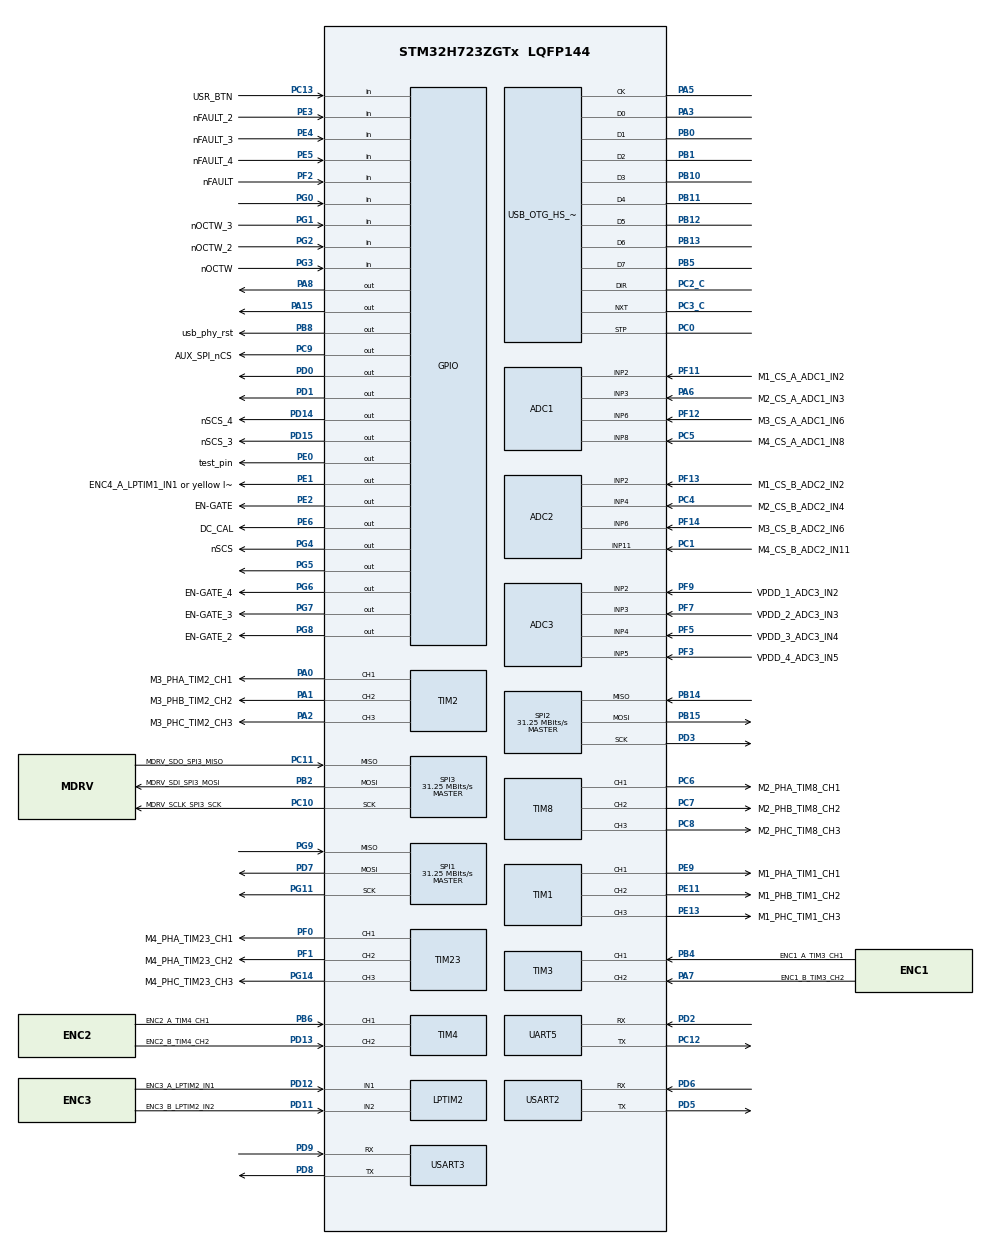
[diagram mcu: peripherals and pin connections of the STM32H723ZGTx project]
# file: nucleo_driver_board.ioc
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ADC1.Channel-0\#ChannelRegularConversion=ADC_CHANNEL_2
ADC1.ClockPrescaler=ADC_CLOCK_ASYNC_DIV4
ADC1.NbrOfConversionFlag=1
ADC1.OffsetNumber-0\#ChannelRegularConversion=ADC_OFFSET_NONE
ADC1.OffsetSignedSaturation-0\#ChannelRegularConversion=DISABLE
ADC1.Rank-0\#ChannelRegularConversion=1
ADC1.SamplingTime-0\#ChannelRegularConversion=ADC_SAMPLETIME_1CYCLE_5
ADC1.master=1
ADC2.Channel-4\#ChannelRegularConversion=ADC_CHANNEL_6
ADC2.ClockPrescaler=ADC_CLOCK_ASYNC_DIV4
ADC2.NbrOfConversionFlag=1
ADC2.OffsetNumber-4\#ChannelRegularConversion=ADC_OFFSET_NONE
ADC2.OffsetSignedSaturation-4\#ChannelRegularConversion=DISABLE
ADC2.Rank-4\#ChannelRegularConversion=1
ADC2.SamplingTime-4\#ChannelRegularConversion=ADC_SAMPLETIME_1CYCLE_5
ADC3.Channel-1\#ChannelRegularConversion=ADC_CHANNEL_2
ADC3.ClockPrescaler=ADC_CLOCK_ASYNC_DIV4
ADC3.NbrOfConversionFlag=1
ADC3.OffsetNumber-1\#ChannelRegularConversion=ADC_OFFSET_NONE
ADC3.OffsetSign-1\#ChannelRegularConversion=ADC3_OFFSET_SIGN_NEGATIVE
ADC3.Rank-1\#ChannelRegularConversion=1
ADC3.SamplingTime-1\#ChannelRegularConversion=ADC3_SAMPLETIME_2CYCLES_5
CORTEX_M7.CPU_DCache=Enabled
CORTEX_M7.CPU_ICache=Enabled
CORTEX_M7.default_mode_Activation=1
Mcu.Family=STM32H7
Mcu.Name=STM32H723ZGTx
Mcu.Package=LQFP144
NVIC.PriorityGroup=NVIC_PRIORITYGROUP_4
PA0.GPIO_Label=M3_PHA_TIM2_CH1
PA0.Signal=S_TIM2_CH1_ETR
PA1.GPIO_Label=M3_PHB_TIM2_CH2
PA1.Signal=S_TIM2_CH2
PA13(JTMS/SWDIO).Mode=Trace_Asynchronous_SW
PA13(JTMS/SWDIO).Signal=DEBUG_JTMS-SWDIO
PA14(JTCK/SWCLK).Mode=Trace_Asynchronous_SW
PA14(JTCK/SWCLK).Signal=DEBUG_JTCK-SWCLK
PA15(JTDI).Signal=GPIO_Output
PA2.GPIO_Label=M3_PHC_TIM2_CH3
PA2.Signal=S_TIM2_CH3
PA3.Mode=Device_HS
PA3.Signal=USB_OTG_HS_ULPI_D0
PA5.Mode=Device_HS
PA5.Signal=USB_OTG_HS_ULPI_CK
PA6.GPIO_Label=M2_CS_A_ADC1_IN3
PA6.Signal=ADCx_INP3
PA7.GPIO_Label=ENC1_B_TIM3_CH2
PA7.Signal=S_TIM3_CH2
PA8.Signal=GPIO_Output
PA9.Signal=USART1_TX
PB0.Mode=Device_HS
PB0.Signal=USB_OTG_HS_ULPI_D1
PB1.Mode=Device_HS
PB1.Signal=USB_OTG_HS_ULPI_D2
PB10.Mode=Device_HS
PB10.Signal=USB_OTG_HS_ULPI_D3
PB11.Mode=Device_HS
PB11.Signal=USB_OTG_HS_ULPI_D4
PB12.Mode=Device_HS
PB12.Signal=USB_OTG_HS_ULPI_D5
PB13.Mode=Device_HS
PB13.Signal=USB_OTG_HS_ULPI_D6
PB14.Mode=Full_Duplex_Master
PB14.Signal=SPI2_MISO
PB15.Mode=Full_Duplex_Master
PB15.Signal=SPI2_MOSI
PB2.GPIO_Label=MDRV_SDI_SPI3_MOSI
PB2.Mode=Full_Duplex_Master
PB2.Signal=SPI3_MOSI
PB3(JTDO/TRACESWO).Mode=Trace_Asynchronous_SW
PB3(JTDO/TRACESWO).Signal=DEBUG_JTDO-SWO
PB4(NJTRST).GPIO_Label=ENC1_A_TIM3_CH1
PB4(NJTRST).Signal=S_TIM3_CH1
PB5.Mode=Device_HS
PB5.Signal=USB_OTG_HS_ULPI_D7
PB6.GPIO_Label=ENC2_A_TIM4_CH1
PB6.Signal=S_TIM4_CH1
PB7.Signal=USART1_RX
PB8.GPIO_Label=usb_phy_rst
PB8.Signal=GPIO_Output
PC0.Mode=Device_HS
PC0.Signal=USB_OTG_HS_ULPI_STP
PC1.GPIO_Label=M4_CS_B_ADC2_IN11
PC1.Signal=ADCx_INP11
PC10.GPIO_Label=MDRV_SCLK_SPI3_SCK
PC10.Mode=Full_Duplex_Master
PC10.Signal=SPI3_SCK
PC11.GPIO_Label=MDRV_SDO_SPI3_MISO
PC11.Mode=Full_Duplex_Master
PC11.Signal=SPI3_MISO
PC12.Mode=Asynchronous
PC12.Signal=UART5_TX
PC13.GPIO_Label=USR_BTN
PC13.Signal=GPIO_Input
PC2_C.Mode=Device_HS
PC2_C.Signal=USB_OTG_HS_ULPI_DIR
PC3_C.Mode=Device_HS
PC3_C.Signal=USB_OTG_HS_ULPI_NXT
PC4.GPIO_Label=M2_CS_B_ADC2_IN4
PC4.Signal=ADCx_INP4
PC5.GPIO_Label=M4_CS_A_ADC1_IN8
PC5.Signal=ADCx_INP8
PC6.GPIO_Label=M2_PHA_TIM8_CH1
PC6.Signal=S_TIM8_CH1
PC7.GPIO_Label=M2_PHB_TIM8_CH2
PC7.Signal=S_TIM8_CH2
PC8.GPIO_Label=M2_PHC_TIM8_CH3
PC8.Signal=S_TIM8_CH3
PC9.GPIO_Label=AUX_SPI_nCS
PC9.Signal=GPIO_Output
PD0.Signal=GPIO_Output
PD1.Signal=GPIO_Output
PD11.GPIO_Label=ENC3_B_LPTIM2_IN2
PD11.Mode=Encoder_mode_occur1
PD11.Signal=LPTIM2_IN2
PD12.GPIO_Label=ENC3_A_LPTIM2_IN1
PD12.Mode=Encoder_mode_occur1
PD12.Signal=LPTIM2_IN1
PD13.GPIO_Label=ENC2_B_TIM4_CH2
PD13.Signal=S_TIM4_CH2
PD14.GPIO_Label=nSCS_4
PD14.Signal=GPIO_Output
PD15.GPIO_Label=nSCS_3
PD15.Signal=GPIO_Output
PD2.Mode=Asynchronous
PD2.Signal=UART5_RX
PD3.Mode=Full_Duplex_Master
PD3.Signal=SPI2_SCK
PD5.Mode=Asynchronous
PD5.Signal=USART2_TX
PD6.Mode=Asynchronous
PD6.Signal=USART2_RX
PD7.Mode=Full_Duplex_Master
PD7.Signal=SPI1_MOSI
PD8.Mode=Asynchronous
PD8.Signal=USART3_TX
PD9.Mode=Asynchronous
PD9.Signal=USART3_RX
PE0.GPIO_Label=test_pin
PE0.Signal=GPIO_Output
PE1.GPIO_Label=ENC4_A_LPTIM1_IN1 or yellow led
PE1.Signal=GPIO_Output
PE11.GPIO_Label=M1_PHB_TIM1_CH2
PE11.Signal=S_TIM1_CH2
PE13.GPIO_Label=M1_PHC_TIM1_CH3
PE13.Signal=S_TIM1_CH3
PE2.GPIO_Label=EN-GATE
PE2.Signal=GPIO_Output
PE3.GPIO_Label=nFAULT_2
PE3.Signal=GPIO_Input
PE4.GPIO_Label=nFAULT_3
PE4.Signal=GPIO_Input
PE5.GPIO_Label=nFAULT_4
PE5.Signal=GPIO_Input
PE6.GPIO_Label=DC_CAL
PE6.Signal=GPIO_Output
PE9.GPIO_Label=M1_PHA_TIM1_CH1
PE9.Signal=S_TIM1_CH1
PF0.GPIO_Label=M4_PHA_TIM23_CH1
PF0.Mode=PWM Generation1 CH1
PF0.Signal=TIM23_CH1
PF1.GPIO_Label=M4_PHA_TIM23_CH2
PF1.Signal=S_TIM23_CH2
PF11.GPIO_Label=M1_CS_A_ADC1_IN2
PF11.Mode=IN2-Single-Ended
PF11.Signal=ADC1_INP2
PF12.GPIO_Label=M3_CS_A_ADC1_IN6
PF12.Mode=IN6-Single-Ended
PF12.Signal=ADC1_INP6
PF13.GPIO_Label=M1_CS_B_ADC2_IN2
PF13.Mode=IN2-Single-Ended
PF13.Signal=ADC2_INP2
PF14.GPIO_Label=M3_CS_B_ADC2_IN6
PF14.Mode=IN6-Single-Ended
PF14.Signal=ADC2_INP6
PF2.GPIO_Label=nFAULT
PF2.Signal=GPIO_Input
PF3.GPIO_Label=VPDD_4_ADC3_IN5
PF3.Mode=IN5-Single-Ended
PF3.Signal=ADC3_INP5
PF5.GPIO_Label=VPDD_3_ADC3_IN4
PF5.Mode=IN4-Single-Ended
PF5.Signal=ADC3_INP4
PF7.GPIO_Label=VPDD_2_ADC3_IN3
PF7.Mode=IN3-Single-Ended
PF7.Signal=ADC3_INP3
PF9.GPIO_Label=VPDD_1_ADC3_IN2
PF9.Mode=IN2-Single-Ended
PF9.Signal=ADC3_INP2
PG0.Signal=GPIO_Input
PG1.GPIO_Label=nOCTW_3
PG1.Signal=GPIO_Input
PG11.Mode=Full_Duplex_Master
PG11.Signal=SPI1_SCK
PG14.GPIO_Label=M4_PHC_TIM23_CH3
PG14.Signal=S_TIM23_CH3
PG2.GPIO_Label=nOCTW_2
PG2.Signal=GPIO_Input
PG3.GPIO_Label=nOCTW
PG3.Signal=GPIO_Input
PG4.GPIO_Label=nSCS
PG4.Signal=GPIO_Output
PG5.Signal=GPIO_Output
PG6.GPIO_Label=EN-GATE_4
PG6.Signal=GPIO_Output
PG7.GPIO_Label=EN-GATE_3
PG7.Signal=GPIO_Output
PG8.GPIO_Label=EN-GATE_2
PG8.Signal=GPIO_Output
PG9.Mode=Full_Duplex_Master
PG9.Signal=SPI1_MISO
PH0-OSC_IN.Mode=HSE-External-Clock-Source
PH0-OSC_IN.Signal=RCC_OSC_IN
ProjectManager.HeapSize=0x200
ProjectManager.StackSize=0x400
ProjectManager.TargetToolchain=Makefile
RCC.ADCCLockSelection=RCC_ADCCLKSOURCE_PLL2
RCC.ADCFreq_Value=62500000
RCC.APB1Freq_Value=137500000
RCC.APB2Freq_Value=137500000
RCC.APB3Freq_Value=137500000
RCC.APB4Freq_Value=137500000
RCC.CECCLockSelection=RCC_CECCLKSOURCE_LSI
RCC.CSI_VALUE=4000000
RCC.CortexFreq_Value=550000000
RCC.D1PPRE=RCC_APB3_DIV2
RCC.D2PPRE1=RCC_APB1_DIV2
RCC.D2PPRE2=RCC_APB2_DIV2
RCC.D3PPRE=RCC_APB4_DIV2
RCC.DIVM1=1
RCC.DIVM2=1
RCC.DIVM3=4
RCC.DIVN1=110
RCC.DIVN2=100
RCC.DIVN3=192
RCC.DIVP1=1
RCC.DIVP2=8
RCC.DIVP3=5
RCC.DIVQ1=5
RCC.DIVQ3=5
RCC.DIVR3=5
RCC.EXTERNAL_CLOCK_VALUE=12288000
RCC.FLatency-AdvancedSettings=FLASH_LATENCY_3
RCC.HCLKFreq_Value=275000000
RCC.HPRE=RCC_HCLK_DIV2
RCC.HSE_VALUE=5000000
RCC.HSI48_VALUE=48000000
RCC.HSI_VALUE=64000000
RCC.I2C123CLockSelection=RCC_I2C1235CLKSOURCE_D2PCLK1
RCC.I2C4CLockSelection=RCC_I2C4CLKSOURCE_D3PCLK1
RCC.LPTIM1CLockSelection=RCC_LPTIM1CLKSOURCE_PLL2
RCC.LPTIM2CLockSelection=RCC_LPTIM2CLKSOURCE_PLL2
RCC.LPTIM345CLockSelection=RCC_LPTIM345CLKSOURCE_D3PCLK1
RCC.LPUART1CLockSelection=RCC_LPUART1CLKSOURCE_D3PCLK1
RCC.LSE_VALUE=32768
RCC.PLL1_VCI_Range-AdvancedSettings=RCC_PLL1VCIRANGE_0
RCC.PLL1_VCO_SEL-AdvancedSettings=RCC_PLL1VCOMEDIUM
RCC.PLL2FRACN=0
RCC.PLL2_VCI_Range-AdvancedSettings=RCC_PLL2VCIRANGE_1
RCC.PLL2_VCO_SEL-AdvancedSettings=RCC_PLL2VCOWIDE
RCC.PLL3FRACN=0
RCC.PLL3_VCO_SEL-AdvancedSettings=RCC_PLL3VCOMEDIUM
RCC.PLLFRACN=0
RCC.PLLSourceVirtual=RCC_PLLSOURCE_HSE
RCC.PWR_Regulator_Voltage_Scale=PWR_REGULATOR_VOLTAGE_SCALE0
RCC.RCC_MCO1Source=RCC_MCO1SOURCE_HSI48
RCC.RCC_MCO2Source=RCC_MCO2SOURCE_SYSCLK
RCC.RCC_MCODiv1=RCC_MCODIV_2
RCC.RNGCLockSelection=RCC_RNGCLKSOURCE_HSI48
RCC.SAI1CLockSelection=RCC_SAI1CLKSOURCE_PLL
RCC.SAI4ACLockSelection=RCC_SAI4ACLKSOURCE_PLL
RCC.SAI4BCLockSelection=RCC_SAI4BCLKSOURCE_PLL
RCC.SPI123CLockSelection=RCC_SPI123CLKSOURCE_PLL2
RCC.SPI6CLockSelection=RCC_SPI6CLKSOURCE_D3PCLK1
RCC.SYSCLKFreq_VALUE=550000000
RCC.SYSCLKSource=RCC_SYSCLKSOURCE_PLLCLK
RCC.Spi45ClockSelection=RCC_SPI45CLKSOURCE_D2PCLK1
RCC.USART16CLockSelection=RCC_USART16910CLKSOURCE_D2PCLK2
RCC.USBCLockSelection=RCC_USBCLKSOURCE_PLL3
RCC.USBFreq_Value=48000000
SH.ADCx_INP11.0=ADC2_INP11,IN11-Single-Ended
SH.ADCx_INP3.0=ADC1_INP3,IN3-Single-Ended
SH.ADCx_INP4.0=ADC2_INP4,IN4-Single-Ended
SH.ADCx_INP8.0=ADC1_INP8,IN8-Single-Ended
SH.S_TIM1_CH1.0=TIM1_CH1,PWM Generation1 CH1
SH.S_TIM1_CH2.0=TIM1_CH2,PWM Generation2 CH2
SH.S_TIM1_CH3.0=TIM1_CH3,PWM Generation3 CH3
SH.S_TIM23_CH2.0=TIM23_CH2,PWM Generation2 CH2
SH.S_TIM23_CH3.0=TIM23_CH3,PWM Generation3 CH3
SH.S_TIM2_CH1_ETR.0=TIM2_CH1,PWM Generation1 CH1
SH.S_TIM2_CH2.0=TIM2_CH2,PWM Generation2 CH2
SH.S_TIM2_CH3.0=TIM2_CH3,PWM Generation3 CH3
SH.S_TIM3_CH1.0=TIM3_CH1,Encoder_Interface
SH.S_TIM3_CH2.0=TIM3_CH2,Encoder_Interface
SH.S_TIM4_CH1.0=TIM4_CH1,Encoder_Interface
SH.S_TIM4_CH2.0=TIM4_CH2,Encoder_Interface
SH.S_TIM8_CH1.0=TIM8_CH1,PWM Generation1 CH1
SH.S_TIM8_CH2.0=TIM8_CH2,PWM Generation2 CH2
SH.S_TIM8_CH3.0=TIM8_CH3,PWM Generation3 CH3
SPI1.BaudRatePrescaler=SPI_BAUDRATEPRESCALER_2
SPI1.CalculateBaudRate=31.25 MBits/s
SPI1.Direction=SPI_DIRECTION_2LINES
SPI1.Mode=SPI_MODE_MASTER
SPI1.VirtualType=VM_MASTER
SPI2.BaudRatePrescaler=SPI_BAUDRATEPRESCALER_2
SPI2.CalculateBaudRate=31.25 MBits/s
SPI2.Direction=SPI_DIRECTION_2LINES
SPI2.Mode=SPI_MODE_MASTER
SPI2.VirtualType=VM_MASTER
SPI3.BaudRatePrescaler=SPI_BAUDRATEPRESCALER_2
SPI3.CalculateBaudRate=31.25 MBits/s
SPI3.Direction=SPI_DIRECTION_2LINES
SPI3.Mode=SPI_MODE_MASTER
SPI3.VirtualType=VM_MASTER
TIM1.Channel-PWM\ Generation1\ CH1=TIM_CHANNEL_1
TIM1.Channel-PWM\ Generation2\ CH2=TIM_CHANNEL_2
TIM1.Channel-PWM\ Generation3\ CH3=TIM_CHANNEL_3
TIM2.Channel-PWM\ Generation1\ CH1=TIM_CHANNEL_1
TIM2.Channel-PWM\ Generation2\ CH2=TIM_CHANNEL_2
TIM2.Channel-PWM\ Generation3\ CH3=TIM_CHANNEL_3
TIM23.Channel-PWM\ Generation1\ CH1=TIM_CHANNEL_1
TIM23.Channel-PWM\ Generation2\ CH2=TIM_CHANNEL_2
TIM23.Channel-PWM\ Generation3\ CH3=TIM_CHANNEL_3
TIM24.AutoReloadPreload=TIM_AUTORELOAD_PRELOAD_ENABLE
TIM24.Period=10000
TIM24.Prescaler=27
TIM3.EncoderMode=TIM_ENCODERMODE_TI12
TIM4.EncoderMode=TIM_ENCODERMODE_TI12
TIM6.AutoReloadPreload=TIM_AUTORELOAD_PRELOAD_ENABLE
TIM6.Period=10000
TIM6.Prescaler=47
TIM8.Channel-PWM\ Generation1\ CH1=TIM_CHANNEL_1
TIM8.Channel-PWM\ Generation2\ CH2=TIM_CHANNEL_2
TIM8.Channel-PWM\ Generation3\ CH3=TIM_CHANNEL_3
USART2.VirtualMode-Asynchronous=VM_ASYNC
USART3.VirtualMode-Asynchronous=VM_ASYNC
VP_MEMORYMAP_VS_MEMORYMAP.Mode=CurAppReg
VP_TIM24_VS_ClockSourceINT.Mode=Internal
VP_TIM5_VS_ClockSourceINT.Mode=Internal
VP_TIM6_VS_ClockSourceINT.Mode=Enable_Timer
board=custom

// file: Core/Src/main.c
/* USER CODE BEGIN Header */
/**
 ******************************************************************************
 * @file           : main.c
 * @brief          : Main program body
 ******************************************************************************
 * @attention
 *
 * Copyright (c) 2024 STMicroelectronics.
 * All rights reserved.
 *
 * This software is licensed under terms that can be found in the LICENSE file
 * in the root directory of this software component.
 * If no LICENSE file comes with this software, it is provided AS-IS.
 *
 ******************************************************************************
 */
/* USER CODE END Header */
#include "main.h"
#include "adc.h"
#include "gpio.h"
#include "lptim.h"
#include "spi.h"
#include "stm32h7xx_hal.h"
#include "stm32h7xx_hal_gpio.h"
#include "tim.h"
#include "usart.h"
#include "usb_otg.h"

/* USER CODE BEGIN Includes */
#include "../../App/src/scheduler_timer.c"
#include "../../App/src/usb_descriptors.c"
#include "usbd.h"
#define VENDOR_REQUEST_CUSTOM_COMMAND 42
#define min(a, b) (((a) < (b)) ? (a) : (b))
#include "SEGGER_RTT.h"
#include "node_time.h"
#include "sched_servo.h"
#include "tusb.h"
#include <inttypes.h>
#include <stdio.h>
#include <string.h>

int __io_putchar(int ch) {
  SEGGER_RTT_PutChar(0, ch);
  // tud_cdc_n_write_char(1, ch);
  // tud_cdc_n_write_str(0, "putchar!\n");
  // tud_cdc_n_write_flush(0);
  // if (ch == '\n') {
  //   tud_cdc_n_write_flush(0);
  // }
  return ch;
}
/* USER CODE END Includes */

/* USER CODE BEGIN PTD */
// void OTG_FS_IRQHandler(void) { tusb_int_handler(0, true); }
void OTG_HS_IRQHandler(void) {
  tud_int_handler(1);
  // tusb_int_handler(0, true);
  // printf("USB IRQ\n");
}
void OTG_HS_EP1_IN_IRQHandler(void) {
  printf("USB EP1 IN IRQ\n");
  tusb_int_handler(1, true);
};
void OTG_HS_EP1_OUT_IRQHandler(void) {
  printf("USB EP1 OUT IRQ\n");
  tusb_int_handler(1, true);
};

// uint8_t to_send[6] = {0, 1, 2, 3, 4, 5};
// uint8_t rxbuf[64] = {0};
// bool custom_command_cb(uint8_t rhport, uint8_t stage,
//                        tusb_control_request_t const *request) {
//   bool result = false;
//   int len = 0;
//
//   if (rhport != BOARD_TUD_RHPORT)
//     return result;
//
//   if (request->bmRequestType_bit.direction == TUSB_DIR_IN) {
//     // TUSB_DIR_IN
//     switch (stage) {
//     case CONTROL_STAGE_SETUP:
//       printf("SETUP stage of control transfer IN\n");
//       result = tud_control_xfer(rhport, request, &to_send, sizeof(to_send));
//       break;
//     case CONTROL_STAGE_DATA:
//       printf("DATA stage of control transfer IN\n");
//       result = true;
//       break;
//     case CONTROL_STAGE_ACK:
//       result = true;
//       break;
//     default:
//       break;
//     }
//   } else {
//     // TUSB_DIR_OUT
//     switch (stage) {
//     case CONTROL_STAGE_SETUP: {
//       if (request->wValue == 0xbeef) {
//         // HAL_GPIO_WritePin(LED_RED_GPIO_Port, LED_RED_Pin,
//         (GPIO_PinState)0);
//       } else {
//         // HAL_GPIO_WritePin(LED_RED_GPIO_Port, LED_RED_Pin,
//         (GPIO_PinState)1);
//       }
//     }
//       // result = tud_control_status(rhport, request);
//       len = min(request->wLength, 64);
//       result = tud_control_xfer(rhport, request, rxbuf, len);
//       printf("recieved: ");
//       for (int i = 0; i < len; i++) {
//         printf("%d, ", rxbuf[i]);
//       }
//       printf("\n");
//       break;
//     case CONTROL_STAGE_DATA:
//       printf("DATA stage of control transfer OUT\n");
//       len = min(request->wLength, 64);
//       // result = tud_control_xfer(rhport, request, rxbuf, 0);
//       printf("recieved: ");
//       for (int i = 0; i < len; i++) {
//         printf("%d, ", rxbuf[i]);
//         rxbuf[i] = 0;
//       }
//       printf("\n");
//       result = true;
//       break;
//     case CONTROL_STAGE_ACK:
//       printf("ACK control OUT transfer\n");
//       // len = min(request->wLength, 64);
//       result = true; // tud_control_status(rhport, request);
//       break;
//     default:
//       printf("custom command default branch\n");
//       break;
//     }
//   }
//   return result;
// }
//
// bool tud_vendor_control_xfer_cb(uint8_t rhport, uint8_t stage,
//                                 tusb_control_request_t const *request) {
//   uint8_t recipient = request->bmRequestType_bit.recipient;
//   uint8_t type = request->bmRequestType_bit.type;
//   uint8_t direction = request->bmRequestType_bit.direction;
//
//   printf("Control xfer:\n stage: %d\nrecipient: %d\ntype: %d\ndirection: "
//          "%d\nbRequest: %d\nwValue: 0x%x\nwIndex: %d\nwLength: %d\n\n",
//          stage, recipient, type, direction, request->bRequest,
//          request->wValue, request->wIndex, request->wLength);
//
//   bool result = false;
//   switch (request->bmRequestType_bit.type) {
//   case TUSB_REQ_TYPE_VENDOR:
//     switch (request->bRequest) {
//     case VENDOR_REQUEST_CUSTOM_COMMAND:
//       result = custom_command_cb(rhport, stage, request);
//       break;
//     }
//     break;
//   case TUSB_REQ_TYPE_STANDARD:
//     break;
//   case TUSB_REQ_TYPE_CLASS:
//     break;
//   default:
//     break;
//   }
//   printf("result: %d\n", result);
//   printf("********\n\n");
//   return result;
// }
void Enable_USB_IRQs() {
  // HAL_NVIC_SetPriority(OTG_HS_EP1_OUT_IRQn, 0, 0);
  // HAL_NVIC_EnableIRQ(OTG_HS_EP1_OUT_IRQn);
  // HAL_NVIC_SetPriority(OTG_HS_EP1_IN_IRQn, 0, 0);
  // HAL_NVIC_EnableIRQ(OTG_HS_EP1_IN_IRQn);
  HAL_NVIC_SetPriority(OTG_HS_IRQn, 1, 0);
  HAL_NVIC_EnableIRQ(OTG_HS_IRQn);
}

/* USER CODE END PTD */

/* USER CODE BEGIN PV */
#define USBULPI_PHYCR ((uint32_t)(0x40040000 + 0x034))
#define USBULPI_D07 ((uint32_t)0x000000FF)
#define USBULPI_New ((uint32_t)0x02000000)
#define USBULPI_RW ((uint32_t)0x00400000)
#define USBULPI_S_BUSY ((uint32_t)0x04000000)
#define USBULPI_S_DONE ((uint32_t)0x08000000)

#define Pattern_55 ((uint32_t)0x00000055)
#define Pattern_AA ((uint32_t)0x000000AA)

#define PHY_PWR_DOWN (1 << 11)
#define PHY_ADDRESS 0x00 /* default ADDR for PHY: LAN8742 */
#define USBULPI_TIMEOUT_COUNT (100)

#define USB_OTG_READ_REG32(reg) (*(__IO uint32_t *)(reg))
#define USB_OTG_WRITE_REG32(reg, value) (*(__IO uint32_t *)(reg) = (value))

/**
 * @brief  Read CR value
 * @param  Addr the Address of the ULPI Register
 * @retval Returns value of PHY CR register
 */
static uint32_t USB_ULPI_Read(uint32_t Addr) {
  uint32_t val = 0;
  uint32_t timeout = USBULPI_TIMEOUT_COUNT;

  USB_OTG_WRITE_REG32(USBULPI_PHYCR, USBULPI_New | (Addr << 16));
  val = USB_OTG_READ_REG32(USBULPI_PHYCR);
  while (((val & USBULPI_S_DONE) == 0) && (timeout--)) {
    val = USB_OTG_READ_REG32(USBULPI_PHYCR);
  }
  val = USB_OTG_READ_REG32(USBULPI_PHYCR);
  return val & 0x000000ff;
}

/**
 * @brief  Write CR value
 * @param  Addr the Address of the ULPI Register
 * @param  Data Data to write
 * @retval Returns value of PHY CR register
 */
static uint32_t USB_ULPI_Write(uint32_t Addr, uint32_t Data) {
  uint32_t val;
  uint32_t timeout = USBULPI_TIMEOUT_COUNT;

  USB_OTG_WRITE_REG32(USBULPI_PHYCR, USBULPI_New | USBULPI_RW | (Addr << 16) |
                                         (Data & 0x000000ff));
  val = USB_OTG_READ_REG32(USBULPI_PHYCR);
  while (((val & USBULPI_S_DONE) == 0) && (timeout--)) {
    val = USB_OTG_READ_REG32(USBULPI_PHYCR);
  }

  val = USB_OTG_READ_REG32(USBULPI_PHYCR);
  return 0;
}

// sched_servo_fixed_t g_sched_servo;

/* USER CODE END PV */

void SystemClock_Config(void);
void PeriphCommonClock_Config(void);
static void MPU_Config(void);

int main(void) {

  /* MPU Configuration--------------------------------------------------------*/
  MPU_Config();

  /* Enable the CPU Cache */

  /* Enable I-Cache---------------------------------------------------------*/
  SCB_EnableICache();

  /* Enable D-Cache---------------------------------------------------------*/
  SCB_EnableDCache();

  /* MCU Configuration--------------------------------------------------------*/

  /* Reset of all peripherals, Initializes the Flash interface and the Systick.
   */
  HAL_Init();

  /* USER CODE BEGIN Init */
  SEGGER_RTT_Init();
  SEGGER_RTT_ConfigUpBuffer(0, NULL, NULL, 0, SEGGER_RTT_MODE_NO_BLOCK_SKIP);
  /* USER CODE END Init */

  /* Configure the system clock */
  SystemClock_Config();

  /* Configure the peripherals common clocks */
  PeriphCommonClock_Config();

  /* Initialize all configured peripherals */
  MX_GPIO_Init();
  MX_ADC1_Init();
  MX_ADC2_Init();
  MX_TIM1_Init();
  MX_TIM8_Init();
  MX_SPI3_Init();
  MX_TIM3_Init();
  MX_TIM4_Init();
  MX_ADC3_Init();
  MX_LPTIM2_Init();
  MX_SPI1_Init();
  MX_SPI2_Init();
  MX_TIM2_Init();
  MX_TIM23_Init();
  MX_UART5_Init();
  MX_USART2_UART_Init();
  MX_USART3_UART_Init();
  MX_USB_OTG_HS_PCD_Init();
  MX_TIM5_Init();
  MX_TIM6_Init();
  MX_TIM24_Init();
  /* USER CODE BEGIN 2 */

  Enable_USB_IRQs();

  HAL_GPIO_WritePin(GPIOB, GPIO_PIN_8, GPIO_PIN_SET);
  HAL_Delay(100);
  HAL_GPIO_WritePin(GPIOB, GPIO_PIN_8, GPIO_PIN_RESET);
  // do a software reset of the ULPI Phy before we init the usb periph
  // following the tinyusb example lead on this one
  // HAL_Delay(20);
  // uint32_t ulpi_reg = USB_ULPI_Read(0x04);
  // USB_ULPI_Write(0x04, ulpi_reg | 1 << 5);
  // HAL_Delay(20);

  // printf("Starting tinyusb\n");
  tusb_rhport_init_t dev_init = {.role = TUSB_ROLE_DEVICE,
                                 .speed = TUSB_SPEED_HIGH};
  bool initial_init = tusb_rhport_init(1, &dev_init);
  if (!initial_init) {
    printf("USB Init failed :(, %d\n", initial_init);
    while (1) {
      HAL_Delay(100);
    }
  }
  USB_OTG_HS->GOTGCTL &= ~USB_OTG_GOTGCTL_BVALOEN;
  printf("tinyusb started!\n");
  sync_init();
  tim5_init();
  tim_init_for_scheduler();
  /* USER CODE END 2 */

  /* Infinite loop */
  /* USER CODE BEGIN WHILE */
  uint32_t blink_last = board_millis();
  while (1) {
    // uint64_t t_now = node_time_now_ns();
    // printf("time ns: %llu\n", t_now);
    if (board_millis() - blink_last > 500) {
      HAL_GPIO_TogglePin(GPIOE, GPIO_PIN_1);
      blink_last = board_millis();
      // tud_cdc_n_write_str(0, "blink\n");
      // tud_cdc_n_write_flush(0);
    }

    // printf("GINTSTS: %d\n", USB_OTG_HS->GINTSTS);
    int sess_valid = 1 & (USB_OTG_HS->GOTGCTL >> 18);
    // uint32_t sess_valid = USB_OTG_HS->GOTGCTL;
    bool usb_inited = tud_inited();
    int connected = tud_connected();
    int mounted = tud_mounted();
    printf("GOTGCTL: %d, inited: %d, connected: %d, mounted %d\n", sess_valid,
           usb_inited, connected, mounted);
    // if (sess_valid && !connected) {
    //   tud_connect();
    // }
    // if (sess_valid && usb_inited && ~mounted) {
    //   tud_disconnect();
    //   // int deinit = tusb_deinit(1);
    //   // printf("usb deinit: %d\n", deinit);
    // } else if (sess_valid && ~usb_inited) {
    //   // tud_init(1);
    //   tud_connect();
    //   printf("usb init\n");
    // } else if (usb_inited) {
    //   tud_task();
    // }
    board_delay(1000);

    /* USER CODE END WHILE */

  }
}

void SystemClock_Config(void) {
  RCC_OscInitTypeDef RCC_OscInitStruct = {0};
  RCC_ClkInitTypeDef RCC_ClkInitStruct = {0};

  /** Supply configuration update enable
   */
  HAL_PWREx_ConfigSupply(PWR_LDO_SUPPLY);

  /** Configure the main internal regulator output voltage
   */
  __HAL_PWR_VOLTAGESCALING_CONFIG(PWR_REGULATOR_VOLTAGE_SCALE0);

  while (!__HAL_PWR_GET_FLAG(PWR_FLAG_VOSRDY)) {
  }

  /** Initializes the RCC Oscillators according to the specified parameters
   * in the RCC_OscInitTypeDef structure.
   */
  RCC_OscInitStruct.OscillatorType = RCC_OSCILLATORTYPE_HSE;
  RCC_OscInitStruct.HSEState = RCC_HSE_BYPASS;
  RCC_OscInitStruct.PLL.PLLState = RCC_PLL_ON;
  RCC_OscInitStruct.PLL.PLLSource = RCC_PLLSOURCE_HSE;
  RCC_OscInitStruct.PLL.PLLM = 1;
  RCC_OscInitStruct.PLL.PLLN = 110;
  RCC_OscInitStruct.PLL.PLLP = 1;
  RCC_OscInitStruct.PLL.PLLQ = 5;
  RCC_OscInitStruct.PLL.PLLR = 2;
  RCC_OscInitStruct.PLL.PLLRGE = RCC_PLL1VCIRANGE_2;
  RCC_OscInitStruct.PLL.PLLVCOSEL = RCC_PLL1VCOWIDE;
  RCC_OscInitStruct.PLL.PLLFRACN = 0;
  if (HAL_RCC_OscConfig(&RCC_OscInitStruct) != HAL_OK) {
    Error_Handler();
  }

  /** Initializes the CPU, AHB and APB buses clocks
   */
  RCC_ClkInitStruct.ClockType = RCC_CLOCKTYPE_HCLK | RCC_CLOCKTYPE_SYSCLK |
                                RCC_CLOCKTYPE_PCLK1 | RCC_CLOCKTYPE_PCLK2 |
                                RCC_CLOCKTYPE_D3PCLK1 | RCC_CLOCKTYPE_D1PCLK1;
  RCC_ClkInitStruct.SYSCLKSource = RCC_SYSCLKSOURCE_PLLCLK;
  RCC_ClkInitStruct.SYSCLKDivider = RCC_SYSCLK_DIV1;
  RCC_ClkInitStruct.AHBCLKDivider = RCC_HCLK_DIV2;
  RCC_ClkInitStruct.APB3CLKDivider = RCC_APB3_DIV2;
  RCC_ClkInitStruct.APB1CLKDivider = RCC_APB1_DIV2;
  RCC_ClkInitStruct.APB2CLKDivider = RCC_APB2_DIV2;
  RCC_ClkInitStruct.APB4CLKDivider = RCC_APB4_DIV2;

  if (HAL_RCC_ClockConfig(&RCC_ClkInitStruct, FLASH_LATENCY_3) != HAL_OK) {
    Error_Handler();
  }
}

void PeriphCommonClock_Config(void) {
  RCC_PeriphCLKInitTypeDef PeriphClkInitStruct = {0};

  /** Initializes the peripherals clock
   */
  PeriphClkInitStruct.PeriphClockSelection =
      RCC_PERIPHCLK_ADC | RCC_PERIPHCLK_LPTIM2 | RCC_PERIPHCLK_SPI3 |
      RCC_PERIPHCLK_SPI2 | RCC_PERIPHCLK_SPI1;
  PeriphClkInitStruct.PLL2.PLL2M = 1;
  PeriphClkInitStruct.PLL2.PLL2N = 100;
  PeriphClkInitStruct.PLL2.PLL2P = 8;
  PeriphClkInitStruct.PLL2.PLL2Q = 2;
  PeriphClkInitStruct.PLL2.PLL2R = 2;
  PeriphClkInitStruct.PLL2.PLL2RGE = RCC_PLL2VCIRANGE_2;
  PeriphClkInitStruct.PLL2.PLL2VCOSEL = RCC_PLL2VCOWIDE;
  PeriphClkInitStruct.PLL2.PLL2FRACN = 0;
  PeriphClkInitStruct.Spi123ClockSelection = RCC_SPI123CLKSOURCE_PLL2;
  PeriphClkInitStruct.Lptim2ClockSelection = RCC_LPTIM2CLKSOURCE_PLL2;
  PeriphClkInitStruct.AdcClockSelection = RCC_ADCCLKSOURCE_PLL2;
  if (HAL_RCCEx_PeriphCLKConfig(&PeriphClkInitStruct) != HAL_OK) {
    Error_Handler();
  }
}

/* MPU Configuration */

void MPU_Config(void) {
  MPU_Region_InitTypeDef MPU_InitStruct = {0};

  /* Disables the MPU */
  HAL_MPU_Disable();

  /** Initializes and configures the Region and the memory to be protected
   */
  MPU_InitStruct.Enable = MPU_REGION_ENABLE;
  MPU_InitStruct.Number = MPU_REGION_NUMBER0;
  MPU_InitStruct.BaseAddress = 0x0;
  MPU_InitStruct.Size = MPU_REGION_SIZE_4GB;
  MPU_InitStruct.SubRegionDisable = 0x87;
  MPU_InitStruct.TypeExtField = MPU_TEX_LEVEL0;
  MPU_InitStruct.AccessPermission = MPU_REGION_NO_ACCESS;
  MPU_InitStruct.DisableExec = MPU_INSTRUCTION_ACCESS_DISABLE;
  MPU_InitStruct.IsShareable = MPU_ACCESS_SHAREABLE;
  MPU_InitStruct.IsCacheable = MPU_ACCESS_NOT_CACHEABLE;
  MPU_InitStruct.IsBufferable = MPU_ACCESS_NOT_BUFFERABLE;

  HAL_MPU_ConfigRegion(&MPU_InitStruct);
  /* Enables the MPU */
  HAL_MPU_Enable(MPU_PRIVILEGED_DEFAULT);
}

void Error_Handler(void) {
  __disable_irq();
  while (1) {
  }
}
#ifdef USE_FULL_ASSERT
/**
 * @brief  Reports the name of the source file and the source line number
 *         where the assert_param error has occurred.
 * @param  file: pointer to the source file name
 * @param  line: assert_param error line source number
 * @retval None
 */
void assert_failed(uint8_t *file, uint32_t line) {
  /* USER CODE BEGIN 6 */
  /* User can add his own implementation to report the file name and line
     number, ex: printf("Wrong parameters value: file %s on line %d\r\n", file,
     line) */
  /* USER CODE END 6 */
}
#endif /* USE_FULL_ASSERT */
